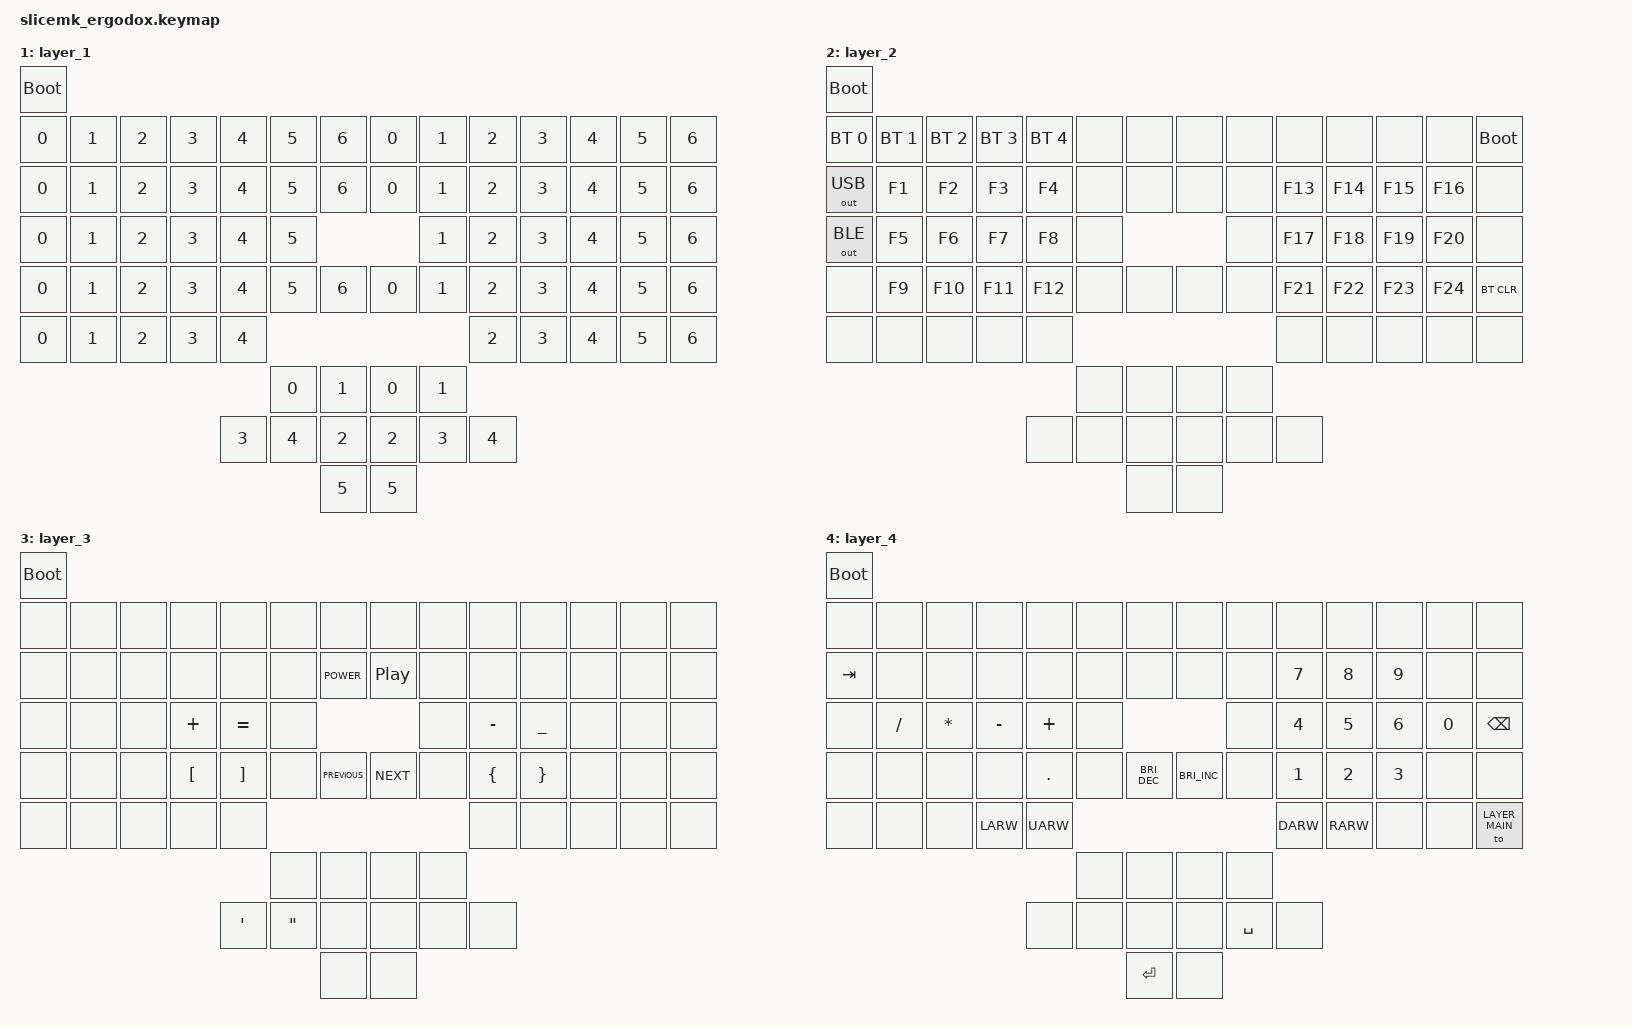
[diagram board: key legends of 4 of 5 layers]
#include <behaviors.dtsi>
#include <dt-bindings/zmk/bt.h>
#include <dt-bindings/zmk/keys.h>
#include <dt-bindings/zmk/outputs.h>
#include <dt-bindings/zmk/rgb.h>
#include <dt-bindings/zmk/backlight.h>



#define LAYER_MAIN 0
#define LAYER_TESTING 1
#define LAYER_FN 2
#define LAYER_SYMB 3
#define LAYER_NMPAD 4



/ {
	keymap {
		compatible = "zmk,keymap";
		layer_0 {
			bindings = <
				&bootloader
				&kp ESC   &kp NUMBER_1 &kp NUMBER_2 &kp NUMBER_3 &kp NUMBER_4 &kp NUMBER_5 &kp NUMBER_6 &kp NUMBER_7 &kp NUMBER_8 &kp NUMBER_9 &kp NUMBER_0 &kp MINUS &kp PLUS      &kp BACKSPACE &rgb_ug RGB_COLOR_HSB(0,100,50)
				&kp TAB   &kp Q        &kp W        &kp E        &kp R        &kp T        &kp NUMBER_6    &kp Y        &kp U        &kp I        &kp O        &kp P     &kp LBKT      &kp RBKT &rgb_ug RGB_COLOR_HSB(0,100,50)
				&kp CAPS  &kp A        &kp S        &kp D        &kp F        &kp G                                  &kp H        &kp J        &kp K        &kp L     &kp SEMICOLON &kp APOS &rgb_ug RGB_COLOR_HSB(0,100,50)
				&kp LSHFT &kp Z        &kp X        &kp C        &kp V        &kp B        &kp NUMBER_6    &kp PIPE     &kp N        &kp M        &kp CMMA     &kp DOT   &kp UP        &kp RCTRL &rgb_ug RGB_COLOR_HSB(0,100,50)
				&kp LCTRL &kp F8       &kp F9       &kp F10      &kp LALT                                                         &kp FSLH     &kp BSLH     &kp LEFT  &kp DOWN      &kp RIGHT &rgb_ug RGB_COLOR_HSB(0,100,50)
				                                                              &kp GRAVE    &kp F3       &kp F6       &kp F7
				                                                 &kp SPACE    &kp LCTRL    &kp F2       &kp F5       &kp ENTER    &kp DEL
				                                                                           &kp F1       &kp F4
			>;
		};
		layer_1 {
			bindings = <
				&bootloader
				&kp NUM_0 &kp NUM_1 &kp NUM_2 &kp NUM_3 &kp NUM_4 &kp NUM_5 &kp NUM_6 &kp NUM_0 &kp NUM_1 &kp NUM_2 &kp NUM_3 &kp NUM_4 &kp NUM_5 &kp NUM_6
				&kp NUM_0 &kp NUM_1 &kp NUM_2 &kp NUM_3 &kp NUM_4 &kp NUM_5 &kp NUM_6 &kp NUM_0 &kp NUM_1 &kp NUM_2 &kp NUM_3 &kp NUM_4 &kp NUM_5 &kp NUM_6
				&kp NUM_0 &kp NUM_1 &kp NUM_2 &kp NUM_3 &kp NUM_4 &kp NUM_5                     &kp NUM_1 &kp NUM_2 &kp NUM_3 &kp NUM_4 &kp NUM_5 &kp NUM_6
				&kp NUM_0 &kp NUM_1 &kp NUM_2 &kp NUM_3 &kp NUM_4 &kp NUM_5 &kp NUM_6 &kp NUM_0 &kp NUM_1 &kp NUM_2 &kp NUM_3 &kp NUM_4 &kp NUM_5 &kp NUM_6
				&kp NUM_0 &kp NUM_1 &kp NUM_2 &kp NUM_3 &kp NUM_4                                         &kp NUM_2 &kp NUM_3 &kp NUM_4 &kp NUM_5 &kp NUM_6
				                                                  &kp NUM_0 &kp NUM_1 &kp NUM_0 &kp NUM_1
				                                        &kp NUM_3 &kp NUM_4 &kp NUM_2 &kp NUM_2 &kp NUM_3 &kp NUM_4
				                                                            &kp NUM_5 &kp NUM_5
			>;
		};
		layer_2 {
			bindings = <
				&bootloader
				&bt BT_SEL 0 &bt BT_SEL 1 &bt BT_SEL 2 &bt BT_SEL 3 &bt BT_SEL 4 &none &none &none &none &none   &none   &none   &none   &bootloader
				&out OUT_USB &kp F1       &kp F2       &kp F3       &kp F4       &none &none &none &none &kp F13 &kp F14 &kp F15 &kp F16 &none
				&out OUT_BLE &kp F5       &kp F6       &kp F7       &kp F8       &none             &none &kp F17 &kp F18 &kp F19 &kp F20 &none
				&none        &kp F9       &kp F10      &kp F11      &kp F12      &none &none &none &none &kp F21 &kp F22 &kp F23 &kp F24 &bt BT_CLR
				&none        &none        &none        &none        &none                                &none   &none   &none   &none   &none
				                                                                 &none &none &none &none
				                                                    &none        &none &none &none &none &none
				                                                                       &none &none
			>;
		};
		layer_3 {
			bindings = <
				&bootloader
				&none &none &none &none    &none            &none             &none          &none            &none &none          &none           &none &none &none
				&none &none &none &none    &none            &none             &kp C_POWER    &kp C_PLAY_PAUSE &none &none          &none           &none &none &none
				&none &none &none &kp PLUS &kp EQUAL        &none                                             &none &kp MINUS      &kp UNDERSCORE  &none &none &none
				&none &none &none &kp LBKT &kp RBKT         &none             &kp C_PREVIOUS &kp C_NEXT       &none &kp LEFT_BRACE &kp RIGHT_BRACE &none &none &none
				&none &none &none &none    &none                                                                    &none          &none           &none &none &none
				                                            &none             &none          &none            &none
				                           &kp SINGLE_QUOTE &kp DOUBLE_QUOTES &none          &none            &none &none
				                                                              &none          &none
			>;
		};
		layer_4 {
			bindings = <
				&bootloader
				&none   &none     &none        &none     &none    &none &none                &none                &none   &none        &none        &none        &none        &none
				&kp TAB &none     &none        &none     &none    &none &none                &none                &none   &kp NUMBER_7 &kp NUMBER_8 &kp NUMBER_9 &none        &none
				&none   &kp SLASH &kp ASTERISK &kp MINUS &kp PLUS &none                                           &none   &kp NUMBER_4 &kp NUMBER_5 &kp NUMBER_6 &kp NUMBER_0 &kp BKSP
				&none   &none     &none        &none     &kp DOT  &none &kp C_BRIGHTNESS_DEC &kp C_BRIGHTNESS_INC &none   &kp NUMBER_1 &kp NUMBER_2 &kp NUMBER_3 &none        &none
				&none   &none     &none        &kp LARW  &kp UARW                                                         &kp DARW     &kp RARW     &none        &none        &to LAYER_MAIN
				                                                  &none &none                &none                &none
				                                         &none    &none &none                &none                &kp SPC &none
				                                                        &kp RET              &none
			>;
		};
	};

};
